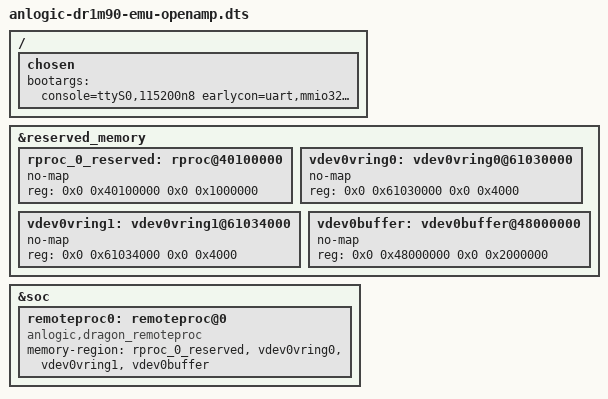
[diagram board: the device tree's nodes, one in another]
// SPDX-License-Identifier: (GPL-2.0+ OR MIT)

/dts-v1/;
#include "anlogic-dr1m90-emu.dts"

/ {
	chosen {
		bootargs = "console=ttyS0,115200n8 earlycon=uart,mmio32,0xf8400000 loglevel=8 maxcpus=1";
	};
};

&reserved_memory {
	/* Reserved memory for loading remote firmware */
	rproc_0_reserved: rproc@40100000 {
		no-map;
		/* 16MB in DDR */
		reg = <0x0 0x40100000 0x0 0x1000000>;
	};

	/* Reserved memory for vring0 */
	vdev0vring0: vdev0vring0@61030000 {
		no-map;
		/* 16KB in OCM */
		reg = <0x0 0x61030000 0x0 0x4000>;
	};

	/* Reserved memory for vring1 */
	vdev0vring1: vdev0vring1@61034000 {
		no-map;
		/* 16KB in OCM */
		reg = <0x0 0x61034000 0x0 0x4000>;
	};

	/* Reserved memory for shared buffer */
	vdev0buffer: vdev0buffer@48000000 {
		no-map;
		/* 32MB in DDR */
		reg = <0x0 0x48000000 0x0 0x2000000>;
	};
};

&soc {
	remoteproc0: remoteproc@0 {
		compatible = "anlogic,dragon_remoteproc";
		memory-region = <&rproc_0_reserved>, <&vdev0vring0>, <&vdev0vring1>, <&vdev0buffer>;
		/*anlogic,no-openamp;*/
	};
};
